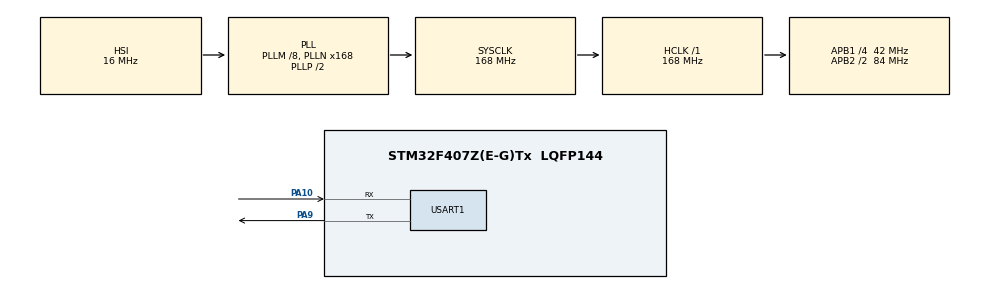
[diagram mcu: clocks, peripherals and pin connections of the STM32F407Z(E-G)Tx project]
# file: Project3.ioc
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FREERTOS.Queues01=Queue01,256,uint8_t,0,Dynamic,NULL,NULL
FREERTOS.Tasks01=Sender1,0,512,StartSender1,Default,NULL,Dynamic,NULL,NULL;Receiver,0,512,StartReceiver,Default,NULL,Dynamic,NULL,NULL
FREERTOS.configUSE_CO_ROUTINES=0
FREERTOS.configUSE_PREEMPTION=1
Mcu.Family=STM32F4
Mcu.Name=STM32F407Z(E-G)Tx
Mcu.Package=LQFP144
NVIC.PriorityGroup=NVIC_PRIORITYGROUP_4
NVIC.TIM2_IRQn=true\:15\:0\:false\:false\:true\:false\:false\:true\:true
NVIC.TimeBase=TIM2_IRQn
NVIC.TimeBaseIP=TIM2
NVIC.USART1_IRQn=true\:5\:0\:false\:false\:true\:true\:true\:true\:true
PA10.Mode=Asynchronous
PA10.Signal=USART1_RX
PA13.Mode=Serial_Wire
PA13.Signal=SYS_JTMS-SWDIO
PA14.Mode=Serial_Wire
PA14.Signal=SYS_JTCK-SWCLK
PA9.Mode=Asynchronous
PA9.Signal=USART1_TX
PC14-OSC32_IN.Mode=LSE-External-Oscillator
PC14-OSC32_IN.Signal=RCC_OSC32_IN
PC15-OSC32_OUT.Mode=LSE-External-Oscillator
PC15-OSC32_OUT.Signal=RCC_OSC32_OUT
PH0-OSC_IN.Mode=HSE-External-Oscillator
PH0-OSC_IN.Signal=RCC_OSC_IN
PH1-OSC_OUT.Mode=HSE-External-Oscillator
PH1-OSC_OUT.Signal=RCC_OSC_OUT
ProjectManager.HeapSize=0x200
ProjectManager.StackSize=0x400
ProjectManager.TargetToolchain=STM32CubeIDE
RCC.48MHZClocksFreq_Value=84000000
RCC.AHBFreq_Value=168000000
RCC.APB1CLKDivider=RCC_HCLK_DIV4
RCC.APB1Freq_Value=42000000
RCC.APB1TimFreq_Value=84000000
RCC.APB2CLKDivider=RCC_HCLK_DIV2
RCC.APB2Freq_Value=84000000
RCC.APB2TimFreq_Value=168000000
RCC.CortexFreq_Value=168000000
RCC.HCLKFreq_Value=168000000
RCC.HSE_VALUE=8000000
RCC.HSI_VALUE=16000000
RCC.PLLM=8
RCC.PLLN=168
RCC.SYSCLKFreq_VALUE=168000000
RCC.SYSCLKSource=RCC_SYSCLKSOURCE_PLLCLK
RCC.VCOOutputFreq_Value=336000000
USART1.VirtualMode=VM_ASYNC
VP_FREERTOS_VS_CMSIS_V1.Mode=CMSIS_V1
VP_SYS_VS_tim2.Mode=TIM2
board=custom

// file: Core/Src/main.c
/* USER CODE BEGIN Header */
/**
  ******************************************************************************
  * @file           : main.c
  * @brief          : Main program body
  ******************************************************************************
  * @attention
  *
  * Copyright (c) 2024 STMicroelectronics.
  * All rights reserved.
  *
  * This software is licensed under terms that can be found in the LICENSE file
  * in the root directory of this software component.
  * If no LICENSE file comes with this software, it is provided AS-IS.
  *
  ******************************************************************************
  */
/* USER CODE END Header */
#include "main.h"
#include "cmsis_os.h"

/* USER CODE BEGIN Includes */
#include "stdio.h"
#include "string.h"
/* USER CODE END Includes */

UART_HandleTypeDef huart1;

osThreadId Sender1Handle;
osThreadId ReceiverHandle;
osMessageQId Queue01Handle;

void SystemClock_Config(void);
static void MX_GPIO_Init(void);
static void MX_USART1_UART_Init(void);
void StartSender1(void const * argument);
void StartReceiver(void const * argument);

/* USER CODE BEGIN PFP */
void AboveNormalTask(void const * parameter); //Named for a task
/* USER CODE END PFP */

/* USER CODE BEGIN 0 */
//print status qua uart
//temp
#ifdef __GNUC__
#define PUTCHAR_PROTOTYPE int __io_putchar(int ch)
#else
#define PUTCHAR_PROTOTYPE int fputc(int ch, FILE *f)
#endif /* __GNUC__ */

PUTCHAR_PROTOTYPE
{
	HAL_UART_Transmit(&huart1, (uint8_t *)&ch, 1, HAL_MAX_DELAY);
	return ch;
}

//void stm32_log(char *s){
//	HAL_UART_Transmit(&huart1, (uint8_t *)s, strlen(s), 10);
//}
/* USER CODE END 0 */

int main(void)
{

  /* MCU Configuration--------------------------------------------------------*/

  /* Reset of all peripherals, Initializes the Flash interface and the Systick. */
  HAL_Init();

  /* Configure the system clock */
  SystemClock_Config();

  /* Initialize all configured peripherals */
  MX_GPIO_Init();
  MX_USART1_UART_Init();
  /* USER CODE BEGIN 2 */
  printf("Application start %d\n");
  /* USER CODE END 2 */

  /* Create the queue(s) */
  /* definition and creation of Queue01 */
  osMessageQDef(Queue01, 256, uint8_t);
  Queue01Handle = osMessageCreate(osMessageQ(Queue01), NULL);

  /* Create the thread(s) */
  /* definition and creation of Sender1 */
  osThreadDef(Sender1, StartSender1, osPriorityNormal, 0, 512);
  Sender1Handle = osThreadCreate(osThread(Sender1), NULL);

  /* definition and creation of Receiver */
  osThreadDef(Receiver, StartReceiver, osPriorityNormal, 0, 512);
  ReceiverHandle = osThreadCreate(osThread(Receiver), NULL);

  /* Start scheduler */
  osKernelStart();

  /* We should never get here as control is now taken by the scheduler */
  /* Infinite loop */
  while (1)
  {

  }
}

void SystemClock_Config(void)
{
  RCC_OscInitTypeDef RCC_OscInitStruct = {0};
  RCC_ClkInitTypeDef RCC_ClkInitStruct = {0};

  /** Configure the main internal regulator output voltage
  */
  __HAL_RCC_PWR_CLK_ENABLE();
  __HAL_PWR_VOLTAGESCALING_CONFIG(PWR_REGULATOR_VOLTAGE_SCALE1);

  /** Initializes the RCC Oscillators according to the specified parameters
  * in the RCC_OscInitTypeDef structure.
  */
  RCC_OscInitStruct.OscillatorType = RCC_OSCILLATORTYPE_HSI;
  RCC_OscInitStruct.HSIState = RCC_HSI_ON;
  RCC_OscInitStruct.HSICalibrationValue = RCC_HSICALIBRATION_DEFAULT;
  RCC_OscInitStruct.PLL.PLLState = RCC_PLL_ON;
  RCC_OscInitStruct.PLL.PLLSource = RCC_PLLSOURCE_HSI;
  RCC_OscInitStruct.PLL.PLLM = 8;
  RCC_OscInitStruct.PLL.PLLN = 168;
  RCC_OscInitStruct.PLL.PLLP = RCC_PLLP_DIV2;
  RCC_OscInitStruct.PLL.PLLQ = 4;
  if (HAL_RCC_OscConfig(&RCC_OscInitStruct) != HAL_OK)
  {
    Error_Handler();
  }

  /** Initializes the CPU, AHB and APB buses clocks
  */
  RCC_ClkInitStruct.ClockType = RCC_CLOCKTYPE_HCLK|RCC_CLOCKTYPE_SYSCLK
                              |RCC_CLOCKTYPE_PCLK1|RCC_CLOCKTYPE_PCLK2;
  RCC_ClkInitStruct.SYSCLKSource = RCC_SYSCLKSOURCE_PLLCLK;
  RCC_ClkInitStruct.AHBCLKDivider = RCC_SYSCLK_DIV1;
  RCC_ClkInitStruct.APB1CLKDivider = RCC_HCLK_DIV4;
  RCC_ClkInitStruct.APB2CLKDivider = RCC_HCLK_DIV2;

  if (HAL_RCC_ClockConfig(&RCC_ClkInitStruct, FLASH_LATENCY_5) != HAL_OK)
  {
    Error_Handler();
  }
}

static void MX_USART1_UART_Init(void)
{

  huart1.Instance = USART1;
  huart1.Init.BaudRate = 115200;
  huart1.Init.WordLength = UART_WORDLENGTH_8B;
  huart1.Init.StopBits = UART_STOPBITS_1;
  huart1.Init.Parity = UART_PARITY_NONE;
  huart1.Init.Mode = UART_MODE_TX_RX;
  huart1.Init.HwFlowCtl = UART_HWCONTROL_NONE;
  huart1.Init.OverSampling = UART_OVERSAMPLING_16;
  if (HAL_UART_Init(&huart1) != HAL_OK)
  {
    Error_Handler();
  }

}

static void MX_GPIO_Init(void)
{

  /* GPIO Ports Clock Enable */
  __HAL_RCC_GPIOC_CLK_ENABLE();
  __HAL_RCC_GPIOH_CLK_ENABLE();
  __HAL_RCC_GPIOA_CLK_ENABLE();

}

void StartSender1(void const * argument)
{
  /* USER CODE BEGIN 5 */
  /* Infinite loop */
	for(;;)
	  {
		  printf("Task1 \n");
		  osMessagePut(Queue01Handle,0x1,200);
		  printf("Task1 delay \n");
		  osDelay(1000);
	  }
  /* USER CODE END 5 */
}

void StartReceiver(void const * argument)
{
  /* USER CODE BEGIN StartReceiver */
	osEvent retvalue;
  /* Infinite loop */
  for(;;)
  {
	  printf("Task2 \n");
	  retvalue=osMessageGet(Queue01Handle,4000);
	  printf("Received value: %lu\n",retvalue.value.p);
  }
  /* USER CODE END StartReceiver */
}

void HAL_TIM_PeriodElapsedCallback(TIM_HandleTypeDef *htim)
{
  if (htim->Instance == TIM2) {
    HAL_IncTick();
  }
}

void Error_Handler(void)
{
  __disable_irq();
  while (1)
  {
  }
}
